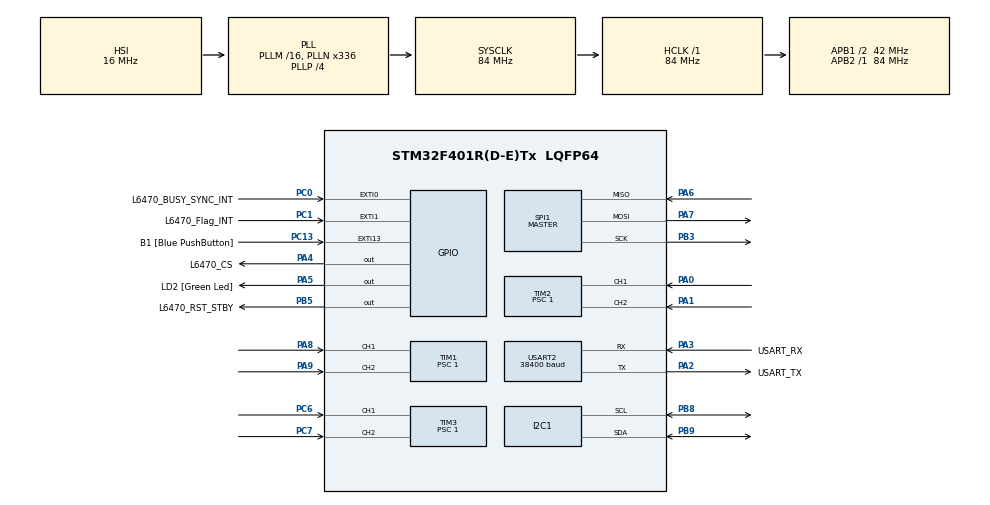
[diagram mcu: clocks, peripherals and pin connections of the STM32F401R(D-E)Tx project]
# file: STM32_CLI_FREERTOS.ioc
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Dma.Request0=USART2_RX
Dma.USART2_RX.0.Direction=DMA_PERIPH_TO_MEMORY
Dma.USART2_RX.0.FIFOMode=DMA_FIFOMODE_DISABLE
Dma.USART2_RX.0.Instance=DMA1_Stream5
Dma.USART2_RX.0.MemDataAlignment=DMA_MDATAALIGN_BYTE
Dma.USART2_RX.0.MemInc=DMA_MINC_ENABLE
Dma.USART2_RX.0.Mode=DMA_CIRCULAR
Dma.USART2_RX.0.PeriphDataAlignment=DMA_PDATAALIGN_BYTE
Dma.USART2_RX.0.PeriphInc=DMA_PINC_DISABLE
Dma.USART2_RX.0.Priority=DMA_PRIORITY_MEDIUM
I2C1.DualAddressMode=I2C_DUALADDRESS_DISABLE
I2C1.I2C_Mode=I2C_Fast
I2C1.NoStretchMode=I2C_NOSTRETCH_DISABLE
Mcu.Family=STM32F4
Mcu.Name=STM32F401R(D-E)Tx
Mcu.Package=LQFP64
NVIC.DMA1_Stream5_IRQn=true\:0\:0\:false\:false\:true\:false\:true
NVIC.EXTI0_IRQn=true\:0\:0\:false\:false\:true\:true\:true
NVIC.EXTI15_10_IRQn=true\:0\:0\:false\:false\:true\:true\:true
NVIC.EXTI1_IRQn=true\:0\:0\:false\:false\:true\:true\:true
NVIC.PriorityGroup=NVIC_PRIORITYGROUP_0
PA0-WKUP.Signal=S_TIM2_CH1_ETR
PA1.Signal=S_TIM2_CH2
PA13.GPIO_Label=TMS
PA13.Mode=Serial_Wire
PA13.Signal=SYS_JTMS-SWDIO
PA14.GPIO_Label=TCK
PA14.Mode=Serial_Wire
PA14.Signal=SYS_JTCK-SWCLK
PA2.GPIO_Label=USART_TX
PA2.GPIO_Mode=GPIO_MODE_AF_PP
PA2.GPIO_PuPd=GPIO_NOPULL
PA2.GPIO_Speed=GPIO_SPEED_FREQ_LOW
PA2.Mode=Asynchronous
PA2.Signal=USART2_TX
PA3.GPIO_Label=USART_RX
PA3.GPIO_Mode=GPIO_MODE_AF_PP
PA3.GPIO_PuPd=GPIO_NOPULL
PA3.GPIO_Speed=GPIO_SPEED_FREQ_LOW
PA3.Mode=Asynchronous
PA3.Signal=USART2_RX
PA4.GPIO_Label=L6470_CS
PA4.PinState=GPIO_PIN_SET
PA4.Signal=GPIO_Output
PA5.GPIO_Label=LD2 [Green Led]
PA5.GPIO_Mode=GPIO_MODE_OUTPUT_PP
PA5.GPIO_PuPd=GPIO_NOPULL
PA5.GPIO_Speed=GPIO_SPEED_FREQ_LOW
PA5.Signal=GPIO_Output
PA6.Mode=Full_Duplex_Master
PA6.Signal=SPI1_MISO
PA7.Mode=Full_Duplex_Master
PA7.Signal=SPI1_MOSI
PA8.Signal=S_TIM1_CH1
PA9.Signal=S_TIM1_CH2
PB3.Mode=Full_Duplex_Master
PB3.Signal=SPI1_SCK
PB5.GPIO_Label=L6470_RST_STBY
PB5.GPIO_ModeDefaultOutputPP=GPIO_MODE_OUTPUT_OD
PB5.Signal=GPIO_Output
PB6.Signal=S_TIM4_CH1
PB7.Signal=S_TIM4_CH2
PB8.Mode=I2C
PB8.Signal=I2C1_SCL
PB9.Mode=I2C
PB9.Signal=I2C1_SDA
PC0.GPIO_Label=L6470_BUSY_SYNC_INT
PC0.GPIO_ModeDefaultEXTI=GPIO_MODE_IT_RISING
PC0.Signal=GPXTI0
PC1.GPIO_Label=L6470_Flag_INT
PC1.GPIO_ModeDefaultEXTI=GPIO_MODE_IT_FALLING
PC1.Signal=GPXTI1
PC13-ANTI_TAMP.GPIO_Label=B1 [Blue PushButton]
PC13-ANTI_TAMP.GPIO_ModeDefaultEXTI=GPIO_MODE_IT_FALLING
PC13-ANTI_TAMP.GPIO_PuPd=GPIO_NOPULL
PC13-ANTI_TAMP.Signal=GPXTI13
PC14-OSC32_IN.Mode=LSE-External-Oscillator
PC14-OSC32_IN.Signal=RCC_OSC32_IN
PC15-OSC32_OUT.Mode=LSE-External-Oscillator
PC15-OSC32_OUT.Signal=RCC_OSC32_OUT
PC6.Signal=S_TIM3_CH1
PC7.Signal=S_TIM3_CH2
PH0\ -\ OSC_IN.Mode=HSE-External-Clock-Source
PH0\ -\ OSC_IN.Signal=RCC_OSC_IN
PH1\ -\ OSC_OUT.Mode=HSE-External-Clock-Source
PH1\ -\ OSC_OUT.Signal=RCC_OSC_OUT
ProjectManager.HeapSize=0x200
ProjectManager.StackSize=0x1000
ProjectManager.TargetToolchain=TrueSTUDIO
RCC.48MHZClocksFreq_Value=48000000
RCC.AHBFreq_Value=84000000
RCC.APB1CLKDivider=RCC_HCLK_DIV2
RCC.APB1Freq_Value=42000000
RCC.APB1TimFreq_Value=84000000
RCC.APB2Freq_Value=84000000
RCC.APB2TimFreq_Value=84000000
RCC.CortexFreq_Value=84000000
RCC.HCLKFreq_Value=84000000
RCC.HSE_VALUE=8000000
RCC.HSI_VALUE=16000000
RCC.PLLN=336
RCC.PLLP=RCC_PLLP_DIV4
RCC.PLLQ=7
RCC.SYSCLKFreq_VALUE=84000000
RCC.SYSCLKSource=RCC_SYSCLKSOURCE_PLLCLK
RCC.VCOOutputFreq_Value=336000000
SH.S_TIM1_CH1.0=TIM1_CH1,Encoder_Interface
SH.S_TIM1_CH2.0=TIM1_CH2,Encoder_Interface
SH.S_TIM2_CH1_ETR.0=TIM2_CH1,Encoder_Interface
SH.S_TIM2_CH2.0=TIM2_CH2,Encoder_Interface
SH.S_TIM3_CH1.0=TIM3_CH1,Encoder_Interface
SH.S_TIM3_CH2.0=TIM3_CH2,Encoder_Interface
SH.S_TIM4_CH1.0=TIM4_CH1
SH.S_TIM4_CH2.0=TIM4_CH2
SPI1.BaudRatePrescaler=SPI_BAUDRATEPRESCALER_16
SPI1.CLKPhase=SPI_PHASE_2EDGE
SPI1.CLKPolarity=SPI_POLARITY_HIGH
SPI1.Direction=SPI_DIRECTION_2LINES
SPI1.Mode=SPI_MODE_MASTER
SPI1.VirtualType=VM_MASTER
TIM1.AutoReloadPreload=TIM_AUTORELOAD_PRELOAD_DISABLE
TIM1.EncoderMode=TIM_ENCODERMODE_TI12
TIM1.IC1Polarity=TIM_ICPOLARITY_FALLING
TIM1.IC2Polarity=TIM_ICPOLARITY_FALLING
TIM1.Period=0xFFFF
TIM1.Prescaler=1
TIM2.EncoderMode=TIM_ENCODERMODE_TI12
TIM2.IC1Polarity=TIM_ICPOLARITY_FALLING
TIM2.IC2Polarity=TIM_ICPOLARITY_FALLING
TIM2.Period=0xFFFF
TIM2.Prescaler=1
TIM3.EncoderMode=TIM_ENCODERMODE_TI12
TIM3.IC1Polarity=TIM_ICPOLARITY_FALLING
TIM3.IC2Polarity=TIM_ICPOLARITY_FALLING
TIM3.Period=0xFFFF
TIM3.Prescaler=1
USART2.BaudRate=38400
USART2.VirtualMode=VM_ASYNC
board=NUCLEO-F401RE

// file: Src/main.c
/* USER CODE BEGIN Header */
/**
  ******************************************************************************
  * @file           : main.c
  * @brief          : Main program body
  ******************************************************************************
  * @attention
  *
  * <h2><center>&copy; Copyright (c) 2019 STMicroelectronics.
  * All rights reserved.</center></h2>
  *
  * This software component is licensed by ST under BSD 3-Clause license,
  * the "License"; You may not use this file except in compliance with the
  * License. You may obtain a copy of the License at:
  *                        opensource.org/licenses/BSD-3-Clause
  *
  ******************************************************************************
  */
/* USER CODE END Header */

#include <cli_uart_interface.h>
#include "main.h"
#include "dma.h"
#include "i2c.h"
#include "spi.h"
#include "tim.h"
#include "usart.h"
#include "gpio.h"

/* USER CODE BEGIN Includes */
#include "motor_config.h"
#include "cli_commands.h"
#include "encoder_interface.h"
#include "L6470.h"

/* USER CODE END Includes */

void SystemClock_Config(void);

int main(void)
{

  /* MCU Configuration--------------------------------------------------------*/

  /* Reset of all peripherals, Initializes the Flash interface and the Systick. */
  HAL_Init();

  /* Configure the system clock */
  SystemClock_Config();

  /* Initialize all configured peripherals */
  MX_GPIO_Init();
  MX_DMA_Init();
  MX_SPI1_Init();
  MX_TIM1_Init();
  MX_USART2_UART_Init();
  MX_TIM2_Init();
  MX_I2C1_Init();
  MX_TIM3_Init();
  /* USER CODE BEGIN 2 */

  Motor_Config();

  CLI_UART_Init();

  CLI_Add_All_Commands();

  Encoder_Interface_Config();

  /* USER CODE END 2 */

  /* Infinite loop */
  while (1)
  {

    /* USER CODE BEGIN 3 */
      CLI_UART_Loop();

      Encoder_Loop();

  }
  /* USER CODE END 3 */
}

void SystemClock_Config(void)
{
  RCC_OscInitTypeDef RCC_OscInitStruct = {0};
  RCC_ClkInitTypeDef RCC_ClkInitStruct = {0};

  /** Configure the main internal regulator output voltage
  */
  __HAL_RCC_PWR_CLK_ENABLE();
  __HAL_PWR_VOLTAGESCALING_CONFIG(PWR_REGULATOR_VOLTAGE_SCALE2);
  /** Initializes the CPU, AHB and APB busses clocks
  */
  RCC_OscInitStruct.OscillatorType = RCC_OSCILLATORTYPE_HSI;
  RCC_OscInitStruct.HSIState = RCC_HSI_ON;
  RCC_OscInitStruct.HSICalibrationValue = RCC_HSICALIBRATION_DEFAULT;
  RCC_OscInitStruct.PLL.PLLState = RCC_PLL_ON;
  RCC_OscInitStruct.PLL.PLLSource = RCC_PLLSOURCE_HSI;
  RCC_OscInitStruct.PLL.PLLM = 16;
  RCC_OscInitStruct.PLL.PLLN = 336;
  RCC_OscInitStruct.PLL.PLLP = RCC_PLLP_DIV4;
  RCC_OscInitStruct.PLL.PLLQ = 7;
  if (HAL_RCC_OscConfig(&RCC_OscInitStruct) != HAL_OK)
  {
    Error_Handler();
  }
  /** Initializes the CPU, AHB and APB busses clocks
  */
  RCC_ClkInitStruct.ClockType = RCC_CLOCKTYPE_HCLK|RCC_CLOCKTYPE_SYSCLK
                              |RCC_CLOCKTYPE_PCLK1|RCC_CLOCKTYPE_PCLK2;
  RCC_ClkInitStruct.SYSCLKSource = RCC_SYSCLKSOURCE_PLLCLK;
  RCC_ClkInitStruct.AHBCLKDivider = RCC_SYSCLK_DIV1;
  RCC_ClkInitStruct.APB1CLKDivider = RCC_HCLK_DIV2;
  RCC_ClkInitStruct.APB2CLKDivider = RCC_HCLK_DIV1;

  if (HAL_RCC_ClockConfig(&RCC_ClkInitStruct, FLASH_LATENCY_2) != HAL_OK)
  {
    Error_Handler();
  }
}

void Error_Handler(void)
{
}

/************************ (C) COPYRIGHT STMicroelectronics *****END OF FILE****/
